# STM32L562 register map
File version: 1.1
Registers are 32-bit, read-write, reset 0x0 unless marked. A register's access mark holds for its fields unless they carry their own. Offsets are from the block's base; lines under a group give offsets from that group; [hi:lo] are bit positions; {n}, {i} and the like mark numbered series; 'fields as' and 'values as' point back to an identical list; <NAME> marks a mode.

## Memory map
0x40010000 SYSCFG size 0x30 — System configuration controller

## SYSCFG — System configuration controller
Base 0x40010000
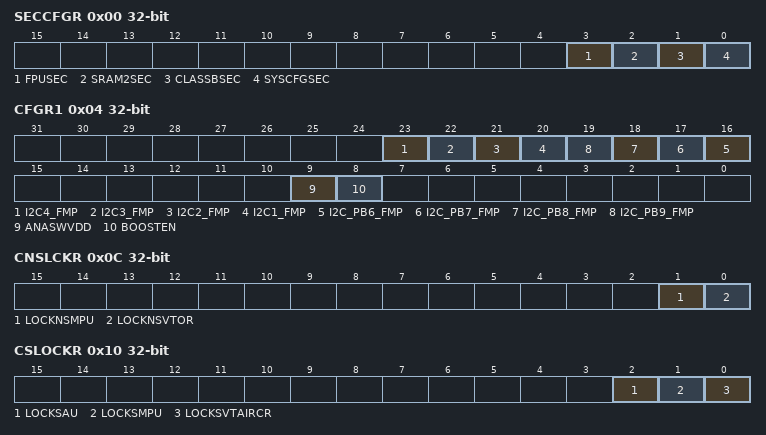
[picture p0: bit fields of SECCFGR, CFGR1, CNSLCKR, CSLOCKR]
0x00 SECCFGR — SYSCFG secure configuration register
  [3] FPUSEC
  [2] SRAM2SEC — SRAM2 security
  [1] CLASSBSEC — ClassB security
  [0] SYSCFGSEC — SYSCFG clock control security
0x04 CFGR1 — configuration register 1
  [23] I2C4_FMP
  [22] I2C3_FMP — I2C3 Fast-mode Plus driving capability activation
  [21] I2C2_FMP — I2C2 Fast-mode Plus driving capability activation
  [20] I2C1_FMP — I2C1 Fast-mode Plus driving capability activation
  [n+10] I2C_PB{n}_FMP (n=6..9) — Fast-mode Plus (Fm+) driving capability activation on PB{n}
  [9] ANASWVDD — GPIO analog switch control voltage selection
  [8] BOOSTEN — I/O analog switch voltage booster enable
0x08 FPUIMR reset 0x1F — FPU interrupt mask register
  [5:0] FPU_IE — Floating point unit interrupts enable bits
0x0C CNSLCKR — SYSCFG CPU non-secure lock register
  [1] LOCKNSMPU — Non-secure MPU registers lock
  [0] LOCKNSVTOR — VTOR_NS register lock
0x10 CSLOCKR — SYSCFG CPU secure lock register
  [2] LOCKSAU, [1] LOCKSMPU, [0] LOCKSVTAIRCR
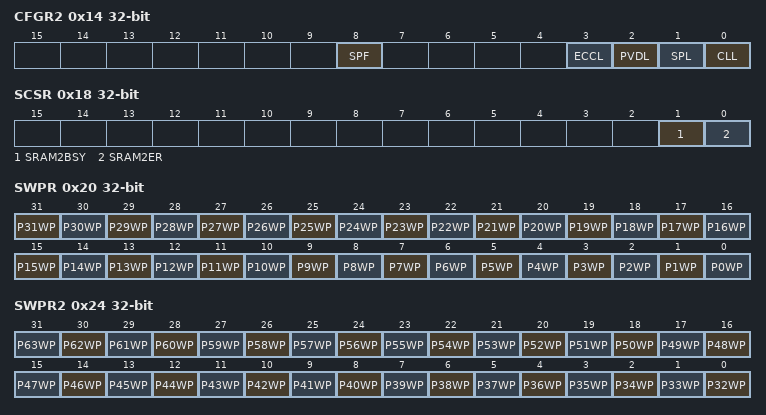
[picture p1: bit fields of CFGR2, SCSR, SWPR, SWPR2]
0x14 CFGR2 access per field
  [8] SPF rw — SRAM2 parity error flag
  [3] ECCL wo — ECC Lock
  [2] PVDL wo — PVD lock enable bit
  [1] SPL wo — SRAM2 parity lock bit
  [0] CLL wo — LOCKUP (hardfault) output enable bit
0x18 SCSR access per field
  [1] SRAM2BSY ro — SRAM2 busy by erase operation
  [0] SRAM2ER rw — SRAM2 Erase
0x1C SKR wo
  [7:0] KEY — SRAM2 write protection key for software erase
0x20 SWPR wo
  [31] P31WP — SRAM2 page 31 write protection
  [n] P{n}WP (n=0..30)
0x24 SWPR2 wo
  [n-32] P{n}WP (n=32..63)
0x2C RSSCMDR
  [7:0] RSSCMD — RSS commands
